AUTOSAR XML (schema 00044)
package /ComponentTypes
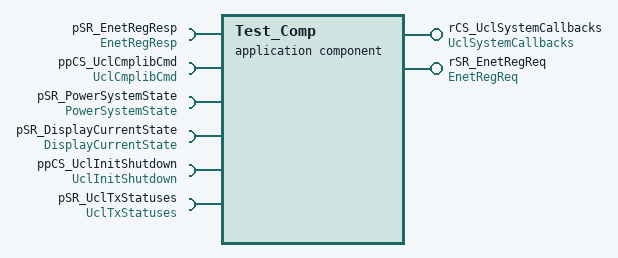
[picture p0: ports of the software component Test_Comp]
  application sw component type Test_Comp
    6 x require port:
      pSR_EnetRegResp: nonqueued-receiver-com-spec{data-element=EnetRegRespData, filter=data-filter-type=ALWAYS, init-value=fields=[EnetReqCmd_t:EnetReqType_Last, uint8:0, data_u8_32:32 x 0]}, required-interface=EnetRegResp
      ppCS_UclCmplibCmd: client-com-spec=OnCommand, required-interface=UclCmplibCmd
      pSR_PowerSystemState: nonqueued-receiver-com-spec{data-element=PowerSystemStateData, filter=data-filter-type=ALWAYS, init-value=fields=[domainId:0, state:0]}, required-interface=PowerSystemState
      pSR_DisplayCurrentState: nonqueued-receiver-com-spec{data-element=DisplayCurrentStateData, filter=data-filter-type=ALWAYS, init-value=fields=[uint32:0, EDisplayStatus:EDisplayState_Last]}, required-interface=DisplayCurrentState
      ppCS_UclInitShutdown: required-com-specs=[Initialize, Shutdown], required-interface=UclInitShutdown
      pSR_UclTxStatuses: required-interface=UclTxStatuses
    provide port rCS_UclSystemCallbacks: provided-com-specs=[{operation=ErrorNotification, queue-length=1}, {operation=LinkStatusChanged, queue-length=1}], provided-interface=UclSystemCallbacks
    provide port rSR_EnetRegReq: nonqueued-sender-com-spec{data-element=EnetRegReqData, init-value=fields=[EnetReqCmd_t:EnetReqType_Last, EnetReqMode_t:EnetReqMode_Last, uint8:0, data_u8_8:8 x 0]}, provided-interface=EnetRegReq
    behavior Test_Comp_InternalBehavior
      operation invoked event OIT_rCS_UclSystemCallbacks_LinkStatusChanged_rCS_UclSystemCallbacks_LinkStatusChanged: start-on-event=rCS_UclSystemCallbacks_LinkStatusChanged, operation=rCS_UclSystemCallbacks.LinkStatusChanged
      operation invoked event OIT_rCS_UclSystemCallbacks_ErrorNotification_rCS_UclSystemCallbacks_ErrorNotification: start-on-event=rCS_UclSystemCallbacks_ErrorNotification, operation=rCS_UclSystemCallbacks.ErrorNotification
      24 x timing event:
        TMT_Test_Comp_MainFunction: start-on-event=Test_Comp_MainFunction, period=0.01
        TMT_EepDrv_MainFunction: start-on-event=EepDrv_MainFunction, period=0.01
        TMT_IoExp_MainFunction: start-on-event=IoExp_MainFunction, period=0.005
        TMT_EthIf_MainFunctionState: start-on-event=EthIf_MainFunctionState, period=0.01
        TMT_EthSM_MainFunction: start-on-event=EthSM_MainFunction, period=0.01
        TMT_TcpIp_MainFunction: start-on-event=TcpIp_MainFunction, period=0.01
        TMT_SoAd_MainFunction: start-on-event=SoAd_MainFunction, period=0.01
        TMT_Com_MainFunctionRx: start-on-event=Com_MainFunctionRx, period=0.01
        TMT_Com_MainFunctionTx: start-on-event=Com_MainFunctionTx, period=0.01
        TMT_CanSM_MainFunction: start-on-event=CanSM_MainFunction, period=0.01
        TMT_Spi_MainFunction_Handling: start-on-event=Spi_MainFunction_Handling, period=0.01
        TMT_I2c_MainFunction: start-on-event=I2c_MainFunction, period=0.01
        TMT_TxRxIpcMessage: start-on-event=TxRxIpcMessage, period=0.01
        TMT_AppTaskStubRunnable: start-on-event=AppTaskStubRunnable, period=0.05
        TMT_AudioTaskStubRunnable: start-on-event=AudioTaskStubRunnable, period=0.03
        TMT_CddTaskStubRunnable: start-on-event=CddTaskStubRunnable, period=0.005
        TMT_FotaTaskStubRunnable: start-on-event=FotaTaskStubRunnable, period=0.1
        TMT_GaugeTaskStubRunnable: start-on-event=GaugeTaskStubRunnable, period=0.02
        TMT_GraphicsTaskStubRunnable: start-on-event=GraphicsTaskStubRunnable, period=0.13
        TMT_IndTaskStubRunnable: start-on-event=IndTaskStubRunnable, period=0.03
        TMT_LinTaskStubRunnable: start-on-event=LinTaskStubRunnable, period=0.02
        TMT_TripTaskStubRunnable: start-on-event=TripTaskStubRunnable, period=0.05
        TMT_WarnTaskStubRunnable: start-on-event=WarnTaskStubRunnable, period=0.03
        TMT_WdgMgntTaskStubRunnable: start-on-event=WdgMgntTaskStubRunnable, period=0.01
      26 x runnable:
        rCS_UclSystemCallbacks_LinkStatusChanged
        rCS_UclSystemCallbacks_ErrorNotification
        Test_Comp_MainFunction
          data-receive-point-by-arguments:
            access REC_pSR_DisplayCurrentState_DisplayCurrentStateData: accessed-variable=pSR_DisplayCurrentState.DisplayCurrentStateData
            access REC_pSR_EnetRegResp_EnetRegRespData: accessed-variable=pSR_EnetRegResp.EnetRegRespData
            access REC_pSR_PowerSystemState_PowerSystemStateData: accessed-variable=pSR_PowerSystemState.PowerSystemStateData
          data-send-points:
            access SEND_rSR_EnetRegReq_EnetRegReqData: accessed-variable=rSR_EnetRegReq.EnetRegReqData
          sync call SC_ppCS_UclCmplibCmd_OnCommand: operation=ppCS_UclCmplibCmd.OnCommand
          sync call SC_ppCS_UclInitShutdown_Initialize: operation=ppCS_UclInitShutdown.Initialize
          sync call SC_ppCS_UclInitShutdown_Shutdown: operation=ppCS_UclInitShutdown.Shutdown
        EepDrv_MainFunction: can-be-invoked-concurrently=true
        IoExp_MainFunction: can-be-invoked-concurrently=true
        EthIf_MainFunctionState: can-be-invoked-concurrently=true
        EthSM_MainFunction: can-be-invoked-concurrently=true
        TcpIp_MainFunction: can-be-invoked-concurrently=true
        SoAd_MainFunction: can-be-invoked-concurrently=true
        Com_MainFunctionRx: can-be-invoked-concurrently=true
        Com_MainFunctionTx: can-be-invoked-concurrently=true
        CanSM_MainFunction: can-be-invoked-concurrently=true
        Spi_MainFunction_Handling: can-be-invoked-concurrently=true
        I2c_MainFunction: can-be-invoked-concurrently=true
        TxRxIpcMessage: can-be-invoked-concurrently=true
        AppTaskStubRunnable
        AudioTaskStubRunnable
        CddTaskStubRunnable
        FotaTaskStubRunnable
        GaugeTaskStubRunnable
        GraphicsTaskStubRunnable
        IndTaskStubRunnable
        LinTaskStubRunnable
        TripTaskStubRunnable
        WarnTaskStubRunnable
        WdgMgntTaskStubRunnable
  swc implementation Test_Comp_Implementation: behavior=Test_Comp_InternalBehavior
    code-descriptors:
      code Default: artifact-descriptors=autosar-engineering-object=category=SWSRC
